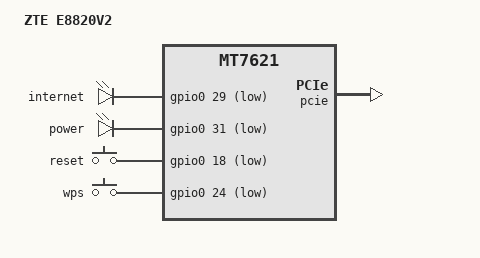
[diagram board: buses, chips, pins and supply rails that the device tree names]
/dts-v1/;

#include "mt7621.dtsi"
#include <dt-bindings/input/input.h>
#include "mt7621-spi-16m-layout.dtsi"
#include "mt7621-raeth-gmac2.dtsi"
#include "mt7621-pinctrl-default-gpio.dtsi"

/ {
	compatible = "mediatek,mt7621-soc";
	model = "ZTE E8820V2";

	chosen {
		bootargs = "console=ttyS0,115200";
	};

	leds {
		compatible = "gpio-leds";

		internet {
			label = "internet";
			gpios = <&gpio0 29 GPIO_ACTIVE_LOW>;
		};

		power {
			label = "power";
			gpios = <&gpio0 31 GPIO_ACTIVE_LOW>;
		};
	};

	gpio-keys-polled {
		compatible = "gpio-keys-polled";
		#address-cells = <1>;
		#size-cells = <0>;
		poll-interval = <20>;

		reset {
			label = "reset";
			gpios = <&gpio0 18 GPIO_ACTIVE_LOW>;
			linux,code = <KEY_RESTART>;
		};

		wps {
			label = "wps";
			gpios = <&gpio0 24 GPIO_ACTIVE_LOW>;
			linux,code = <KEY_WPS_BUTTON>;
		};

	};
};

&pcie {
	status = "okay";
};

